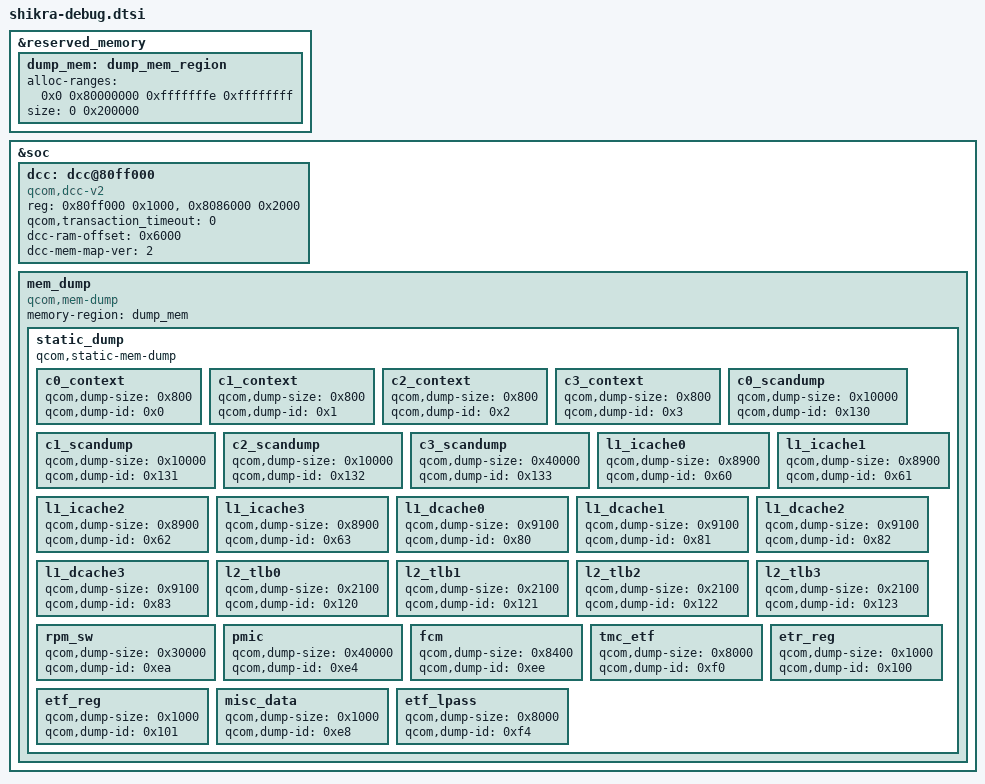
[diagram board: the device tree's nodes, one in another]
// SPDX-License-Identifier: BSD-3-Clause
/*
 * Copyright (c) Qualcomm Technologies, Inc. and/or its subsidiaries.
 */

#include <dt-bindings/soc/qcom,dcc_v2.h>

&reserved_memory {
	#address-cells = <2>;
	#size-cells = <2>;
	ranges;

	dump_mem: dump_mem_region {
		alloc-ranges = <0x0 0x80000000 0xfffffffe 0xffffffff>;
		size = <0 0x200000>;
	};
};

&soc {
	dcc: dcc@80ff000 {
		compatible = "qcom,dcc-v2";
		reg = <0x80ff000 0x1000>,
		      <0x8086000 0x2000>;
		reg-names = "dcc-base", "dcc-ram-base";

		qcom,transaction_timeout = <0>;
		dcc-ram-offset = <0x6000>;

		dcc-mem-map-ver = <2>;
	};

	mem_dump {
		compatible = "qcom,mem-dump";
		memory-region = <&dump_mem>;

		static_dump {
			qcom,static-mem-dump;

			c0_context {
				qcom,dump-size = <0x800>;
				qcom,dump-id = <0x0>;
			};

			c1_context {
				qcom,dump-size = <0x800>;
				qcom,dump-id = <0x1>;
			};

			c2_context {
				qcom,dump-size = <0x800>;
				qcom,dump-id = <0x2>;
			};

			c3_context {
				qcom,dump-size = <0x800>;
				qcom,dump-id = <0x3>;
			};

			c0_scandump {
				qcom,dump-size = <0x10000>;
				qcom,dump-id = <0x130>;
			};

			c1_scandump {
				qcom,dump-size = <0x10000>;
				qcom,dump-id = <0x131>;
			};

			c2_scandump {
				qcom,dump-size = <0x10000>;
				qcom,dump-id = <0x132>;
			};

			c3_scandump {
				qcom,dump-size = <0x40000>;
				qcom,dump-id = <0x133>;
			};

			l1_icache0 {
				qcom,dump-size = <0x8900>;
				qcom,dump-id = <0x60>;
			};

			l1_icache1 {
				qcom,dump-size = <0x8900>;
				qcom,dump-id = <0x61>;
			};

			l1_icache2 {
				qcom,dump-size = <0x8900>;
				qcom,dump-id = <0x62>;
			};

			l1_icache3 {
				qcom,dump-size = <0x8900>;
				qcom,dump-id = <0x63>;
			};

			l1_dcache0 {
				qcom,dump-size = <0x9100>;
				qcom,dump-id = <0x80>;
			};

			l1_dcache1 {
				qcom,dump-size = <0x9100>;
				qcom,dump-id = <0x81>;
			};

			l1_dcache2 {
				qcom,dump-size = <0x9100>;
				qcom,dump-id = <0x82>;
			};

			l1_dcache3 {
				qcom,dump-size = <0x9100>;
				qcom,dump-id = <0x83>;
			};

			l2_tlb0 {
				qcom,dump-size = <0x2100>;
				qcom,dump-id = <0x120>;
			};

			l2_tlb1 {
				qcom,dump-size = <0x2100>;
				qcom,dump-id = <0x121>;
			};

			l2_tlb2 {
				qcom,dump-size = <0x2100>;
				qcom,dump-id = <0x122>;
			};

			l2_tlb3 {
				qcom,dump-size = <0x2100>;
				qcom,dump-id = <0x123>;
			};

			rpm_sw {
				qcom,dump-size = <0x30000>;
				qcom,dump-id = <0xea>;
			};

			pmic {
				qcom,dump-size = <0x40000>;
				qcom,dump-id = <0xe4>;
			};

			fcm {
				qcom,dump-size = <0x8400>;
				qcom,dump-id = <0xee>;
			};

			tmc_etf {
				qcom,dump-size = <0x8000>;
				qcom,dump-id = <0xf0>;
			};

			etr_reg {
				qcom,dump-size = <0x1000>;
				qcom,dump-id = <0x100>;
			};

			etf_reg {
				qcom,dump-size = <0x1000>;
				qcom,dump-id = <0x101>;
			};

			misc_data {
				qcom,dump-size = <0x1000>;
				qcom,dump-id = <0xe8>;
			};

			etf_lpass {
				qcom,dump-size = <0x8000>;
				qcom,dump-id = <0xf4>;
			};
		};
	};
};
